AUTOSAR XML (schema 4-2-2)
package /ComponentTypes
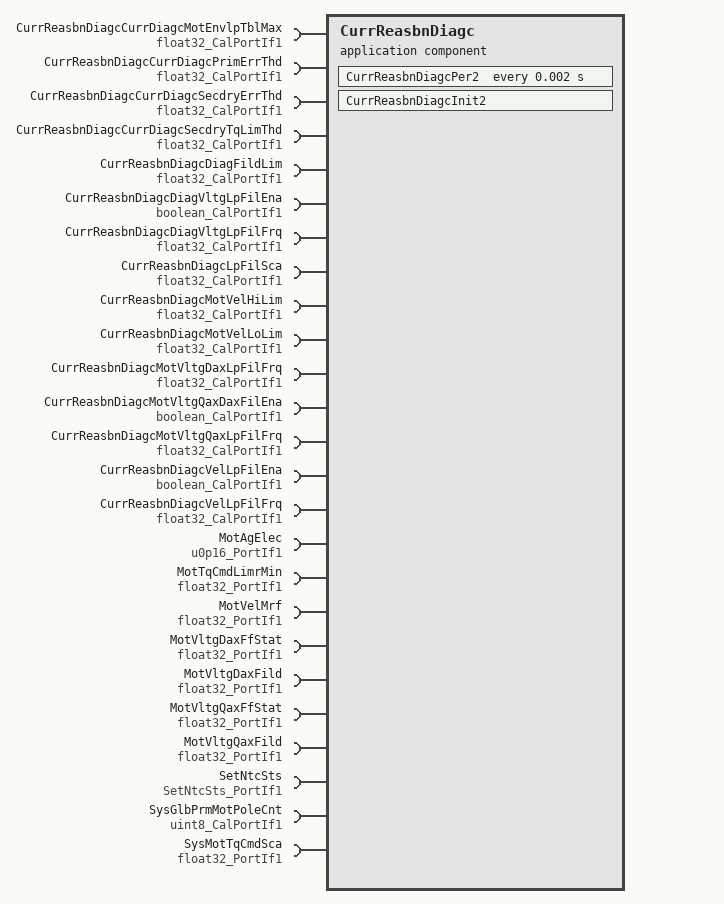
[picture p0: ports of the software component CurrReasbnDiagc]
  application sw component type CurrReasbnDiagc
    25 x require port:
      CurrReasbnDiagcCurrDiagcMotEnvlpTblMax: parameter-require-com-spec{init-value=4.6, parameter=Val}, required-interface=float32_CalPortIf1
      CurrReasbnDiagcCurrDiagcPrimErrThd: parameter-require-com-spec{init-value=20, parameter=Val}, required-interface=float32_CalPortIf1
      CurrReasbnDiagcCurrDiagcSecdryErrThd: parameter-require-com-spec{init-value=20, parameter=Val}, required-interface=float32_CalPortIf1
      CurrReasbnDiagcCurrDiagcSecdryTqLimThd: parameter-require-com-spec{init-value=0, parameter=Val}, required-interface=float32_CalPortIf1
      CurrReasbnDiagcDiagFildLim: parameter-require-com-spec{init-value=10, parameter=Val}, required-interface=float32_CalPortIf1
      CurrReasbnDiagcDiagVltgLpFilEna: parameter-require-com-spec{init-value=1, parameter=Logl}, required-interface=boolean_CalPortIf1
      CurrReasbnDiagcDiagVltgLpFilFrq: parameter-require-com-spec{init-value=5, parameter=Val}, required-interface=float32_CalPortIf1
      CurrReasbnDiagcLpFilSca: parameter-require-com-spec{init-value=0.5, parameter=Val}, required-interface=float32_CalPortIf1
      CurrReasbnDiagcMotVelHiLim: parameter-require-com-spec{init-value=1350, parameter=Val}, required-interface=float32_CalPortIf1
      CurrReasbnDiagcMotVelLoLim: parameter-require-com-spec{init-value=1, parameter=Val}, required-interface=float32_CalPortIf1
      CurrReasbnDiagcMotVltgDaxLpFilFrq: parameter-require-com-spec{init-value=250, parameter=Val}, required-interface=float32_CalPortIf1
      CurrReasbnDiagcMotVltgQaxDaxFilEna: parameter-require-com-spec{init-value=1, parameter=Logl}, required-interface=boolean_CalPortIf1
      CurrReasbnDiagcMotVltgQaxLpFilFrq: parameter-require-com-spec{init-value=250, parameter=Val}, required-interface=float32_CalPortIf1
      CurrReasbnDiagcVelLpFilEna: parameter-require-com-spec{init-value=1, parameter=Logl}, required-interface=boolean_CalPortIf1
      CurrReasbnDiagcVelLpFilFrq: parameter-require-com-spec{init-value=125, parameter=Val}, required-interface=float32_CalPortIf1
      MotAgElec: nonqueued-receiver-com-spec{data-element=Val, filter=data-filter-type=ALWAYS, init-value=0}, required-interface=u0p16_PortIf1
      MotTqCmdLimrMin: nonqueued-receiver-com-spec{data-element=Val, filter=data-filter-type=ALWAYS, init-value=0}, required-interface=float32_PortIf1
      MotVelMrf: nonqueued-receiver-com-spec{data-element=Val, filter=data-filter-type=ALWAYS, init-value=0}, required-interface=float32_PortIf1
      MotVltgDaxFfStat: nonqueued-receiver-com-spec{data-element=Val, filter=data-filter-type=ALWAYS, init-value=0}, required-interface=float32_PortIf1
      MotVltgDaxFild: nonqueued-receiver-com-spec{data-element=Val, filter=data-filter-type=ALWAYS, init-value=0}, required-interface=float32_PortIf1
      MotVltgQaxFfStat: nonqueued-receiver-com-spec{data-element=Val, filter=data-filter-type=ALWAYS, init-value=0}, required-interface=float32_PortIf1
      MotVltgQaxFild: nonqueued-receiver-com-spec{data-element=Val, filter=data-filter-type=ALWAYS, init-value=0}, required-interface=float32_PortIf1
      SetNtcSts: client-com-spec=Oper, required-interface=SetNtcSts_PortIf1
      SysGlbPrmMotPoleCnt: parameter-require-com-spec{init-value=8, parameter=Val}, required-interface=uint8_CalPortIf1
      SysMotTqCmdSca: nonqueued-receiver-com-spec{data-element=Val, filter=data-filter-type=ALWAYS, init-value=1}, required-interface=float32_PortIf1
    behavior CurrReasbnDiagc_InternalBehavior
      ar-typed-per-instance-memorys:
        16 x data, all with sw-calibration-access=READ-ONLY:
          CurrReasbnMotVelLpFil: type=FilLpRec1
          dCurrReasbnDiagcMotVltgAFild: type=float32
          dCurrReasbnDiagcMotVltgBFild: type=float32
          dCurrReasbnDiagcMotVltgDaxDif: type=float32
          dCurrReasbnDiagcMotVltgDiagFild: type=float32
          dCurrReasbnDiagcMotVltgDiagFildLimd: type=float32
          dCurrReasbnDiagcMotVltgDiagSecdryFild: type=float32
          dCurrReasbnDiagcMotVltgQaxDif: type=float32
          dCurrReasbnDiagcVelLpFild: type=float32
          DiagVltgLpFil: type=FilLpRec1
          MotVltgDaxLpFil: type=FilLpRec1
          MotVltgDiagFildInp1Prev: type=float32
          MotVltgDiagFildInp2Prev: type=float32
          MotVltgDiagFildOutp1Prev: type=float32
          MotVltgDiagFildOutp2Prev: type=float32
          MotVltgQaxLpFil: type=FilLpRec1
      init event CurrReasbnDiagc_InitEvent: start-on-event=CurrReasbnDiagcInit2
      timing event TMT_CurrReasbnDiagcPer2: start-on-event=CurrReasbnDiagcPer2, period=0.002
      runnable CurrReasbnDiagcInit2
      runnable CurrReasbnDiagcPer2
        data-receive-point-by-arguments:
          8 x access:
            REC_MotAgElec_Val: accessed-variable=MotAgElec.Val
            REC_MotTqCmdLimrMin_Val: accessed-variable=MotTqCmdLimrMin.Val
            REC_MotVelMrf_Val: accessed-variable=MotVelMrf.Val
            REC_MotVltgDaxFfStat_Val: accessed-variable=MotVltgDaxFfStat.Val
            REC_MotVltgDaxFild_Val: accessed-variable=MotVltgDaxFild.Val
            REC_MotVltgQaxFfStat_Val: accessed-variable=MotVltgQaxFfStat.Val
            REC_MotVltgQaxFild_Val: accessed-variable=MotVltgQaxFild.Val
            REC_SysMotTqCmdSca_Val: accessed-variable=SysMotTqCmdSca.Val
        sync call SC_SetNtcSts_PortIf1_Oper: operation=SetNtcSts.Oper, timeout=0
  swc implementation CurrReasbnDiagc_Implementation: behavior=CurrReasbnDiagc_InternalBehavior
    code-descriptors:
      code Default: artifact-descriptors=autosar-engineering-object={short-label=Default, category=SWSRC}
